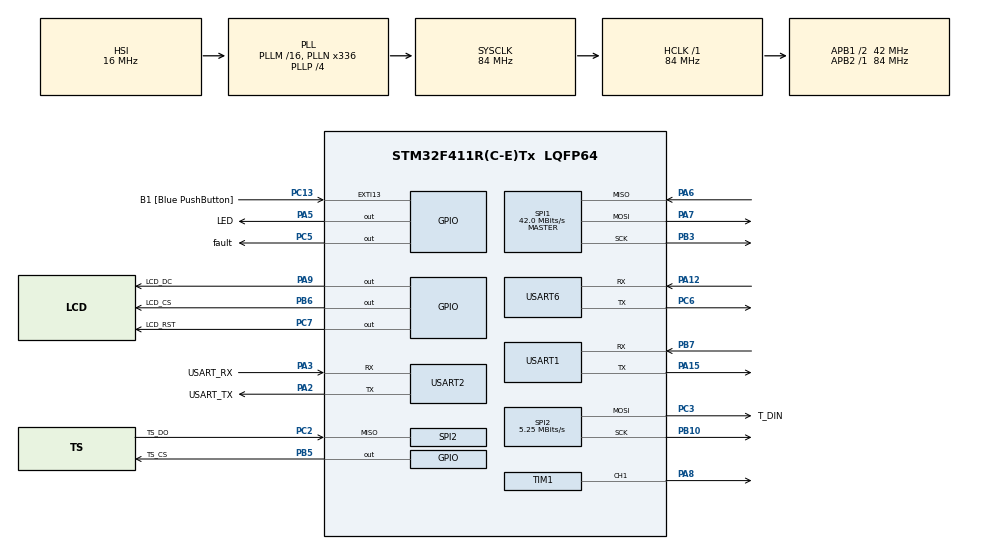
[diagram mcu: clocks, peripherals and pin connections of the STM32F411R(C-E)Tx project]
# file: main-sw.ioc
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Mcu.Family=STM32F4
Mcu.Name=STM32F411R(C-E)Tx
Mcu.Package=LQFP64
NVIC.PriorityGroup=NVIC_PRIORITYGROUP_0
NVIC.TIM3_IRQn=true\:0\:0\:false\:false\:true\:true\:true\:true
NVIC.USART1_IRQn=true\:0\:0\:false\:false\:true\:true\:true\:true
NVIC.USART2_IRQn=true\:0\:0\:false\:false\:true\:true\:true\:true
NVIC.USART6_IRQn=true\:0\:0\:false\:false\:true\:true\:true\:true
PA12.Mode=Asynchronous
PA12.Signal=USART6_RX
PA13.GPIO_Label=TMS
PA13.Mode=Serial_Wire
PA13.Signal=SYS_JTMS-SWDIO
PA14.GPIO_Label=TCK
PA14.Mode=Serial_Wire
PA14.Signal=SYS_JTCK-SWCLK
PA15.Mode=Asynchronous
PA15.Signal=USART1_TX
PA2.GPIO_Label=USART_TX
PA2.Mode=Asynchronous
PA2.Signal=USART2_TX
PA3.GPIO_Label=USART_RX
PA3.Mode=Asynchronous
PA3.Signal=USART2_RX
PA5.GPIO_Label=LED
PA5.Signal=GPIO_Output
PA6.Mode=Full_Duplex_Master
PA6.Signal=SPI1_MISO
PA7.Mode=Full_Duplex_Master
PA7.Signal=SPI1_MOSI
PA8.Signal=S_TIM1_CH1
PA9.GPIO_Label=LCD_DC
PA9.Signal=GPIO_Output
PB10.Mode=Full_Duplex_Master
PB10.Signal=SPI2_SCK
PB3.Mode=Full_Duplex_Master
PB3.Signal=SPI1_SCK
PB5.GPIO_Label=TS_CS
PB5.Signal=GPIO_Output
PB6.GPIO_Label=LCD_CS
PB6.Signal=GPIO_Output
PB7.Mode=Asynchronous
PB7.Signal=USART1_RX
PC13-ANTI_TAMP.GPIO_Label=B1 [Blue PushButton]
PC13-ANTI_TAMP.GPIO_ModeDefaultEXTI=GPIO_MODE_IT_FALLING
PC13-ANTI_TAMP.Signal=GPXTI13
PC14-OSC32_IN.Mode=LSE-External-Oscillator
PC14-OSC32_IN.Signal=RCC_OSC32_IN
PC15-OSC32_OUT.Mode=LSE-External-Oscillator
PC15-OSC32_OUT.Signal=RCC_OSC32_OUT
PC2.GPIO_Label=TS_DO
PC2.Mode=Full_Duplex_Master
PC2.Signal=SPI2_MISO
PC3.GPIO_Label=T_DIN
PC3.Mode=Full_Duplex_Master
PC3.Signal=SPI2_MOSI
PC5.GPIO_Label=fault
PC5.Signal=GPIO_Output
PC6.Mode=Asynchronous
PC6.Signal=USART6_TX
PC7.GPIO_Label=LCD_RST
PC7.Signal=GPIO_Output
PH0\ -\ OSC_IN.Mode=HSE-External-Clock-Source
PH0\ -\ OSC_IN.Signal=RCC_OSC_IN
PH1\ -\ OSC_OUT.Mode=HSE-External-Clock-Source
PH1\ -\ OSC_OUT.Signal=RCC_OSC_OUT
ProjectManager.HeapSize=0x200
ProjectManager.StackSize=0x400
ProjectManager.TargetToolchain=STM32CubeIDE
RCC.48MHZClocksFreq_Value=84000000
RCC.AHBFreq_Value=84000000
RCC.APB1CLKDivider=RCC_HCLK_DIV2
RCC.APB1Freq_Value=42000000
RCC.APB1TimFreq_Value=84000000
RCC.APB2Freq_Value=84000000
RCC.APB2TimFreq_Value=84000000
RCC.CortexFreq_Value=84000000
RCC.FLatency-AdvancedSettings=FLASH_LATENCY_2
RCC.HCLKFreq_Value=84000000
RCC.HSE_VALUE=8000000
RCC.HSI_VALUE=16000000
RCC.PLLN=336
RCC.PLLP=RCC_PLLP_DIV4
RCC.SYSCLKFreq_VALUE=84000000
RCC.SYSCLKSource=RCC_SYSCLKSOURCE_PLLCLK
RCC.VCOOutputFreq_Value=336000000
SH.S_TIM1_CH1.0=TIM1_CH1,PWM Generation1 CH1
SPI1.CalculateBaudRate=42.0 MBits/s
SPI1.Direction=SPI_DIRECTION_2LINES
SPI1.Mode=SPI_MODE_MASTER
SPI1.VirtualType=VM_MASTER
SPI2.BaudRatePrescaler=SPI_BAUDRATEPRESCALER_8
SPI2.CalculateBaudRate=5.25 MBits/s
SPI2.Direction=SPI_DIRECTION_2LINES
SPI2.Mode=SPI_MODE_MASTER
SPI2.VirtualType=VM_MASTER
TIM1.Channel-PWM\ Generation1\ CH1=TIM_CHANNEL_1
TIM1.Prescaler=4
TIM1.Pulse-PWM\ Generation1\ CH1=13125-1
TIM3.Prescaler=4
USART1.VirtualMode=VM_ASYNC
USART2.VirtualMode=VM_ASYNC
USART6.VirtualMode=VM_ASYNC
VP_TIM1_VS_ClockSourceINT.Mode=Internal
VP_TIM3_VS_ClockSourceINT.Mode=Internal
board=NUCLEO-F411RE

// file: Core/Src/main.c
/* USER CODE BEGIN Header */
/**
  ******************************************************************************
  * @file           : main.c
  * @brief          : Main program body
  ******************************************************************************
  * @attention
  *
  * Copyright (c) 2024 STMicroelectronics.
  * All rights reserved.
  *
  * This software is licensed under terms that can be found in the LICENSE file
  * in the root directory of this software component.
  * If no LICENSE file comes with this software, it is provided AS-IS.
  *
  ******************************************************************************
  */
/* USER CODE END Header */
#include "main.h"

/* USER CODE BEGIN Includes */
#include <Kommunikation/pc_recieve_handler.h>
#include <Kommunikation/pc_send_handler.h>
#include <Kommunikation/sensor_recieve_handler.h>
#include <Kommunikation/uart_processor.h>
#include <Kommunikation/uart_data.h>

#include <Management/global_state_machine.h>

#include <SensorActuators/motor.h>
#include <SensorActuators/sensor.h>
#include <Regelung/pid_controller.h>
#include "HMI/hmi_display.h"
#include "HMI/signallight_control.h"
/* USER CODE END Includes */

SPI_HandleTypeDef hspi1;
SPI_HandleTypeDef hspi2;

TIM_HandleTypeDef htim1;
TIM_HandleTypeDef htim3;

UART_HandleTypeDef huart1;
UART_HandleTypeDef huart2;
UART_HandleTypeDef huart6;

/* USER CODE BEGIN PV */
// Aktorik Sensorik
Sensor sensorExtruder;
Sensor sensorBack;
Motor motor;

// State Machein
StateMachine stateMachine;

// Regelung
PIDController pidController;

// KOmmunikation
SensorReceiveHandler sensorReciever;
PcReceiveHandler pcReciever;
PcSendHandler pcSender;

UartDataObject uartDataPc;
UartDataObject uartDataSensorExtruder;
UartDataObject uartDataSensorBack;

// HMI
Hmi hmi;

/* USER CODE END PV */

void SystemClock_Config(void);
static void MX_GPIO_Init(void);
static void MX_SPI1_Init(void);
static void MX_SPI2_Init(void);
static void MX_TIM1_Init(void);
static void MX_USART1_UART_Init(void);
static void MX_USART2_UART_Init(void);
static void MX_USART6_UART_Init(void);
static void MX_TIM3_Init(void);

/* USER CODE BEGIN 0 */
TS_TOUCH_DATA_Def myTS_Handle;
/* USER CODE END 0 */

int main(void)
{

  /* MCU Configuration--------------------------------------------------------*/

  /* Reset of all peripherals, Initializes the Flash interface and the Systick. */
  HAL_Init();

  /* USER CODE BEGIN Init */
  sensorExtruder = initSensor(1.57, 1);
  sensorBack 	 = initSensor(1.58, 6);
  motor 		 = initMotor(&htim1);
  int updateFaultHMI = 1;
  /* USER CODE END Init */

  /* Configure the system clock */
  SystemClock_Config();

  /* Initialize all configured peripherals */
  MX_GPIO_Init();
  MX_SPI1_Init();
  MX_SPI2_Init();
  MX_TIM1_Init();
  MX_USART1_UART_Init();
  MX_USART2_UART_Init();
  MX_USART6_UART_Init();
  MX_TIM3_Init();
  /* USER CODE BEGIN 2 */
  ILI9341_Init(&hspi1, LCD_CS_GPIO_Port, LCD_CS_Pin, LCD_DC_GPIO_Port, LCD_DC_Pin, LCD_RST_GPIO_Port, LCD_RST_Pin);
  ILI9341_setRotation(2);
  ILI9341_Fill(COLOR_NAVY);
  TSC2046_Begin(&hspi2, TS_CS_GPIO_Port, TS_CS_Pin);

  HAL_TIM_PWM_Start(&htim1, 0);
  stateMachine = initStateMachine(&motor,&htim3,2.3);
  pidController = pid_init(5.0, 0.0,0.0, 2);
  uartDataPc 		     = createUartDataObject();
  uartDataSensorExtruder = createUartDataObject();
  uartDataSensorBack	 = createUartDataObject();
  pcSender 		= createPcSendHandler(10);
  pcReciever 	= createPcReceiveHandler(&stateMachine,&pidController, &motor, &pcSender, &huart2);
  sensorReciever = createSensorReceiveHandler(&sensorExtruder, &sensorBack,&stateMachine, &hmi);
  HAL_UART_Receive_IT(&huart1, (uint8_t *)uartDataSensorExtruder.data.receivedData, 1);
  HAL_UART_Receive_IT(&huart6, (uint8_t *)uartDataSensorBack.data.receivedData, 1);
  HAL_UART_Receive_IT(&huart2, (uint8_t *)uartDataPc.data.receivedData, 1);

  hmi = HMI_init(&stateMachine, &sensorExtruder, &sensorBack);

  HAL_GPIO_WritePin(GPIOB, MOTOR_GND_Pin, GPIO_PIN_RESET);
  motor.setSpeed(&motor,0);

  /* USER CODE END 2 */

  /* Infinite loop */
  while (1)
  {

    /* USER CODE BEGIN 3 */
	  // Check Blob Detected
	  //stateMachine.checkBlobDetected(&stateMachine,sensorBack.getDiameter(&sensorBack));

	  myTS_Handle = TSC2046_GetTouchData();
	  HMI_getTouch(&hmi, myTS_Handle,&motor, &pidController);
	  updateFaultHMI = HMI_checkBlob(&hmi, myTS_Handle, updateFaultHMI);
	  HMI_signallight_check_blob(&stateMachine, fault_Pin);

	  if(uartDataPc.data.messageComplete){
		processPcInterfaceMessage(&pcReciever, uartDataPc.data.receivedData, uartDataPc.data.dataIndex);
		// Zurücksetzen für die nächste Nachricht
		uartDataPc.data.messageComplete = 0;
		uartDataPc.data.dataIndex = 0;
		HAL_UART_Receive_IT(&huart2, (uint8_t *)uartDataPc.data.receivedData, 1);

	  }
	  if(uartDataSensorExtruder.data.messageComplete){
		processSensorInterfaceMessage(1,&sensorReciever, uartDataSensorExtruder.data.receivedData, uartDataSensorExtruder.data.dataIndex);
		// Zurücksetzen für die nächste Nachricht
		uartDataSensorExtruder.data.messageComplete = 0;
		uartDataSensorExtruder.data.dataIndex = 0;
		HAL_UART_Receive_IT(&huart1, (uint8_t *)uartDataSensorExtruder.data.receivedData, 1);
	  }
	  if(uartDataSensorBack.data.messageComplete){
		processSensorInterfaceMessage(6,&sensorReciever, uartDataSensorBack.data.receivedData, uartDataSensorBack.data.dataIndex);
		// Zurücksetzen für die nächste Nachricht
		uartDataSensorBack.data.messageComplete = 0;
		uartDataSensorBack.data.dataIndex = 0;
		HAL_UART_Receive_IT(&huart6, (uint8_t *)uartDataSensorBack.data.receivedData, 1);
	  }

  }
  /* USER CODE END 3 */
}

void SystemClock_Config(void)
{
  RCC_OscInitTypeDef RCC_OscInitStruct = {0};
  RCC_ClkInitTypeDef RCC_ClkInitStruct = {0};

  /** Configure the main internal regulator output voltage
  */
  __HAL_RCC_PWR_CLK_ENABLE();
  __HAL_PWR_VOLTAGESCALING_CONFIG(PWR_REGULATOR_VOLTAGE_SCALE1);

  /** Initializes the RCC Oscillators according to the specified parameters
  * in the RCC_OscInitTypeDef structure.
  */
  RCC_OscInitStruct.OscillatorType = RCC_OSCILLATORTYPE_HSI;
  RCC_OscInitStruct.HSIState = RCC_HSI_ON;
  RCC_OscInitStruct.HSICalibrationValue = RCC_HSICALIBRATION_DEFAULT;
  RCC_OscInitStruct.PLL.PLLState = RCC_PLL_ON;
  RCC_OscInitStruct.PLL.PLLSource = RCC_PLLSOURCE_HSI;
  RCC_OscInitStruct.PLL.PLLM = 16;
  RCC_OscInitStruct.PLL.PLLN = 336;
  RCC_OscInitStruct.PLL.PLLP = RCC_PLLP_DIV4;
  RCC_OscInitStruct.PLL.PLLQ = 4;
  if (HAL_RCC_OscConfig(&RCC_OscInitStruct) != HAL_OK)
  {
    Error_Handler();
  }

  /** Initializes the CPU, AHB and APB buses clocks
  */
  RCC_ClkInitStruct.ClockType = RCC_CLOCKTYPE_HCLK|RCC_CLOCKTYPE_SYSCLK
                              |RCC_CLOCKTYPE_PCLK1|RCC_CLOCKTYPE_PCLK2;
  RCC_ClkInitStruct.SYSCLKSource = RCC_SYSCLKSOURCE_PLLCLK;
  RCC_ClkInitStruct.AHBCLKDivider = RCC_SYSCLK_DIV1;
  RCC_ClkInitStruct.APB1CLKDivider = RCC_HCLK_DIV2;
  RCC_ClkInitStruct.APB2CLKDivider = RCC_HCLK_DIV1;

  if (HAL_RCC_ClockConfig(&RCC_ClkInitStruct, FLASH_LATENCY_2) != HAL_OK)
  {
    Error_Handler();
  }
}

static void MX_SPI1_Init(void)
{

  /* SPI1 parameter configuration*/
  hspi1.Instance = SPI1;
  hspi1.Init.Mode = SPI_MODE_MASTER;
  hspi1.Init.Direction = SPI_DIRECTION_2LINES;
  hspi1.Init.DataSize = SPI_DATASIZE_8BIT;
  hspi1.Init.CLKPolarity = SPI_POLARITY_LOW;
  hspi1.Init.CLKPhase = SPI_PHASE_1EDGE;
  hspi1.Init.NSS = SPI_NSS_SOFT;
  hspi1.Init.BaudRatePrescaler = SPI_BAUDRATEPRESCALER_2;
  hspi1.Init.FirstBit = SPI_FIRSTBIT_MSB;
  hspi1.Init.TIMode = SPI_TIMODE_DISABLE;
  hspi1.Init.CRCCalculation = SPI_CRCCALCULATION_DISABLE;
  hspi1.Init.CRCPolynomial = 10;
  if (HAL_SPI_Init(&hspi1) != HAL_OK)
  {
    Error_Handler();
  }

}

static void MX_SPI2_Init(void)
{

  /* SPI2 parameter configuration*/
  hspi2.Instance = SPI2;
  hspi2.Init.Mode = SPI_MODE_MASTER;
  hspi2.Init.Direction = SPI_DIRECTION_2LINES;
  hspi2.Init.DataSize = SPI_DATASIZE_8BIT;
  hspi2.Init.CLKPolarity = SPI_POLARITY_LOW;
  hspi2.Init.CLKPhase = SPI_PHASE_1EDGE;
  hspi2.Init.NSS = SPI_NSS_SOFT;
  hspi2.Init.BaudRatePrescaler = SPI_BAUDRATEPRESCALER_8;
  hspi2.Init.FirstBit = SPI_FIRSTBIT_MSB;
  hspi2.Init.TIMode = SPI_TIMODE_DISABLE;
  hspi2.Init.CRCCalculation = SPI_CRCCALCULATION_DISABLE;
  hspi2.Init.CRCPolynomial = 10;
  if (HAL_SPI_Init(&hspi2) != HAL_OK)
  {
    Error_Handler();
  }

}

static void MX_TIM1_Init(void)
{

  TIM_ClockConfigTypeDef sClockSourceConfig = {0};
  TIM_MasterConfigTypeDef sMasterConfig = {0};
  TIM_OC_InitTypeDef sConfigOC = {0};
  TIM_BreakDeadTimeConfigTypeDef sBreakDeadTimeConfig = {0};

  htim1.Instance = TIM1;
  htim1.Init.Prescaler = 4;
  htim1.Init.CounterMode = TIM_COUNTERMODE_UP;
  htim1.Init.Period = 65535;
  htim1.Init.ClockDivision = TIM_CLOCKDIVISION_DIV1;
  htim1.Init.RepetitionCounter = 0;
  htim1.Init.AutoReloadPreload = TIM_AUTORELOAD_PRELOAD_DISABLE;
  if (HAL_TIM_Base_Init(&htim1) != HAL_OK)
  {
    Error_Handler();
  }
  sClockSourceConfig.ClockSource = TIM_CLOCKSOURCE_INTERNAL;
  if (HAL_TIM_ConfigClockSource(&htim1, &sClockSourceConfig) != HAL_OK)
  {
    Error_Handler();
  }
  if (HAL_TIM_PWM_Init(&htim1) != HAL_OK)
  {
    Error_Handler();
  }
  sMasterConfig.MasterOutputTrigger = TIM_TRGO_RESET;
  sMasterConfig.MasterSlaveMode = TIM_MASTERSLAVEMODE_DISABLE;
  if (HAL_TIMEx_MasterConfigSynchronization(&htim1, &sMasterConfig) != HAL_OK)
  {
    Error_Handler();
  }
  sConfigOC.OCMode = TIM_OCMODE_PWM1;
  sConfigOC.Pulse = 13125-1;
  sConfigOC.OCPolarity = TIM_OCPOLARITY_HIGH;
  sConfigOC.OCNPolarity = TIM_OCNPOLARITY_HIGH;
  sConfigOC.OCFastMode = TIM_OCFAST_DISABLE;
  sConfigOC.OCIdleState = TIM_OCIDLESTATE_RESET;
  sConfigOC.OCNIdleState = TIM_OCNIDLESTATE_RESET;
  if (HAL_TIM_PWM_ConfigChannel(&htim1, &sConfigOC, TIM_CHANNEL_1) != HAL_OK)
  {
    Error_Handler();
  }
  sBreakDeadTimeConfig.OffStateRunMode = TIM_OSSR_DISABLE;
  sBreakDeadTimeConfig.OffStateIDLEMode = TIM_OSSI_DISABLE;
  sBreakDeadTimeConfig.LockLevel = TIM_LOCKLEVEL_OFF;
  sBreakDeadTimeConfig.DeadTime = 0;
  sBreakDeadTimeConfig.BreakState = TIM_BREAK_DISABLE;
  sBreakDeadTimeConfig.BreakPolarity = TIM_BREAKPOLARITY_HIGH;
  sBreakDeadTimeConfig.AutomaticOutput = TIM_AUTOMATICOUTPUT_DISABLE;
  if (HAL_TIMEx_ConfigBreakDeadTime(&htim1, &sBreakDeadTimeConfig) != HAL_OK)
  {
    Error_Handler();
  }
  HAL_TIM_MspPostInit(&htim1);

}

static void MX_TIM3_Init(void)
{

  TIM_ClockConfigTypeDef sClockSourceConfig = {0};
  TIM_MasterConfigTypeDef sMasterConfig = {0};

  htim3.Instance = TIM3;
  htim3.Init.Prescaler = 60000;
  htim3.Init.CounterMode = TIM_COUNTERMODE_UP;
  htim3.Init.Period = 3000;
  htim3.Init.ClockDivision = TIM_CLOCKDIVISION_DIV1;
  htim3.Init.AutoReloadPreload = TIM_AUTORELOAD_PRELOAD_DISABLE;
  if (HAL_TIM_Base_Init(&htim3) != HAL_OK)
  {
    Error_Handler();
  }
  sClockSourceConfig.ClockSource = TIM_CLOCKSOURCE_INTERNAL;
  if (HAL_TIM_ConfigClockSource(&htim3, &sClockSourceConfig) != HAL_OK)
  {
    Error_Handler();
  }
  sMasterConfig.MasterOutputTrigger = TIM_TRGO_RESET;
  sMasterConfig.MasterSlaveMode = TIM_MASTERSLAVEMODE_DISABLE;
  if (HAL_TIMEx_MasterConfigSynchronization(&htim3, &sMasterConfig) != HAL_OK)
  {
    Error_Handler();
  }

}

static void MX_USART1_UART_Init(void)
{

  huart1.Instance = USART1;
  huart1.Init.BaudRate = 115200;
  huart1.Init.WordLength = UART_WORDLENGTH_8B;
  huart1.Init.StopBits = UART_STOPBITS_1;
  huart1.Init.Parity = UART_PARITY_NONE;
  huart1.Init.Mode = UART_MODE_TX_RX;
  huart1.Init.HwFlowCtl = UART_HWCONTROL_NONE;
  huart1.Init.OverSampling = UART_OVERSAMPLING_16;
  if (HAL_UART_Init(&huart1) != HAL_OK)
  {
    Error_Handler();
  }

}

static void MX_USART2_UART_Init(void)
{

  huart2.Instance = USART2;
  huart2.Init.BaudRate = 115200;
  huart2.Init.WordLength = UART_WORDLENGTH_8B;
  huart2.Init.StopBits = UART_STOPBITS_1;
  huart2.Init.Parity = UART_PARITY_NONE;
  huart2.Init.Mode = UART_MODE_TX_RX;
  huart2.Init.HwFlowCtl = UART_HWCONTROL_NONE;
  huart2.Init.OverSampling = UART_OVERSAMPLING_16;
  if (HAL_UART_Init(&huart2) != HAL_OK)
  {
    Error_Handler();
  }

}

static void MX_USART6_UART_Init(void)
{

  huart6.Instance = USART6;
  huart6.Init.BaudRate = 115200;
  huart6.Init.WordLength = UART_WORDLENGTH_8B;
  huart6.Init.StopBits = UART_STOPBITS_1;
  huart6.Init.Parity = UART_PARITY_NONE;
  huart6.Init.Mode = UART_MODE_TX_RX;
  huart6.Init.HwFlowCtl = UART_HWCONTROL_NONE;
  huart6.Init.OverSampling = UART_OVERSAMPLING_16;
  if (HAL_UART_Init(&huart6) != HAL_OK)
  {
    Error_Handler();
  }

}

static void MX_GPIO_Init(void)
{
  GPIO_InitTypeDef GPIO_InitStruct = {0};

  /* GPIO Ports Clock Enable */
  __HAL_RCC_GPIOC_CLK_ENABLE();
  __HAL_RCC_GPIOH_CLK_ENABLE();
  __HAL_RCC_GPIOA_CLK_ENABLE();
  __HAL_RCC_GPIOB_CLK_ENABLE();

  /*Configure GPIO pin Output Level */
  HAL_GPIO_WritePin(GPIOA, LED_Pin|LCD_DC_Pin, GPIO_PIN_RESET);

  /*Configure GPIO pin Output Level */
  HAL_GPIO_WritePin(GPIOC, fault_Pin|LCD_RST_Pin, GPIO_PIN_RESET);

  /*Configure GPIO pin Output Level */
  HAL_GPIO_WritePin(GPIOB, TS_CS_Pin|LCD_CS_Pin|MOTOR_GND_Pin, GPIO_PIN_RESET);

  /*Configure GPIO pin : B1_Pin */
  GPIO_InitStruct.Pin = B1_Pin;
  GPIO_InitStruct.Mode = GPIO_MODE_IT_FALLING;
  GPIO_InitStruct.Pull = GPIO_NOPULL;
  HAL_GPIO_Init(B1_GPIO_Port, &GPIO_InitStruct);

  /*Configure GPIO pins : LED_Pin LCD_DC_Pin */
  GPIO_InitStruct.Pin = LED_Pin|LCD_DC_Pin;
  GPIO_InitStruct.Mode = GPIO_MODE_OUTPUT_PP;
  GPIO_InitStruct.Pull = GPIO_NOPULL;
  GPIO_InitStruct.Speed = GPIO_SPEED_FREQ_LOW;
  HAL_GPIO_Init(GPIOA, &GPIO_InitStruct);

  /*Configure GPIO pins : fault_Pin LCD_RST_Pin */
  GPIO_InitStruct.Pin = fault_Pin|LCD_RST_Pin;
  GPIO_InitStruct.Mode = GPIO_MODE_OUTPUT_PP;
  GPIO_InitStruct.Pull = GPIO_NOPULL;
  GPIO_InitStruct.Speed = GPIO_SPEED_FREQ_LOW;
  HAL_GPIO_Init(GPIOC, &GPIO_InitStruct);

  /*Configure GPIO pins : TS_CS_Pin LCD_CS_Pin MOTOR_GND_Pin */
  GPIO_InitStruct.Pin = TS_CS_Pin|LCD_CS_Pin|MOTOR_GND_Pin;
  GPIO_InitStruct.Mode = GPIO_MODE_OUTPUT_PP;
  GPIO_InitStruct.Pull = GPIO_NOPULL;
  GPIO_InitStruct.Speed = GPIO_SPEED_FREQ_LOW;
  HAL_GPIO_Init(GPIOB, &GPIO_InitStruct);

}

/* USER CODE BEGIN 4 */
void processUartData(UART_HandleTypeDef *huart, UartDataObject *uartData) {
  if (uartData->data.dataIndex == 0 && uartData->data.receivedData[0] != '?' && uartData->data.receivedData[0] != '!') {
    // Fehlerhafte Startbyte, Nachricht ignorieren
    uartData->data.dataIndex = 0;
    HAL_UART_Receive_IT(huart, &uartData->data.receivedData[0], 1);
  } else if (uartData->data.receivedData[uartData->data.dataIndex] == '\r' ) {
    uartData->data.receivedData[uartData->data.dataIndex + 1] = '\0';  // Null-Terminierung hinzufügen
    uartData->data.messageComplete = 1;
  } else if (uartData->data.dataIndex >= sizeof(uartData->data.receivedData) - 1) {
    // Zu große Nachricht, zurücksetzen
    uartData->data.dataIndex = 0;
    HAL_UART_Receive_IT(huart, &uartData->data.receivedData[0], 1);
  } else {
    uartData->data.dataIndex++;
    HAL_UART_Receive_IT(huart, (uint8_t *)&uartData->data.receivedData[uartData->data.dataIndex], 1);
  }
}

void HAL_UART_RxCpltCallback(UART_HandleTypeDef *huart) {
  if (huart == &huart2) {
    processUartData(&huart2, &uartDataPc);
  }else if (huart == &huart1){
	processUartData(&huart1, &uartDataSensorExtruder);
  }else if (huart == &huart6){
	  processUartData(&huart6, &uartDataSensorBack);
  }
}

void TIM3_IRQHandler(void)
{
  float diameter = sensorBack.getDiameter(&sensorExtruder);
  float cValue   = pidController.pid_update(&pidController,diameter);

  float speed = motor.getSpeed(&motor);

  if(speed == 0){
	  if(cValue > 1){
		  speed = 10 * cValue;
	  }
  }else{
	  speed = speed + cValue; //* cValue;
  }
  if(speed > 90){
	  speed = 90;
  }

  motor.setSpeed(&motor,speed);
  HAL_TIM_IRQHandler(&htim3);
}

/* USER CODE END 4 */

void Error_Handler(void)
{
  __disable_irq();
  while (1)
  {
  }
}
